# TMS320F280049 register map
Vendor: Texas Instruments; Series: C2000 F28004x; File version: 0.2.0-generated
Registers are 16-bit, read-write, reset 0x0 unless marked. A register's access mark holds for its fields unless they carry their own. Offsets are from the block's base; [hi:lo] are bit positions; {n}, {i} and the like mark numbered series.

## MEMCFGREGS — MEM CFG Registers
Base 0x000BE800
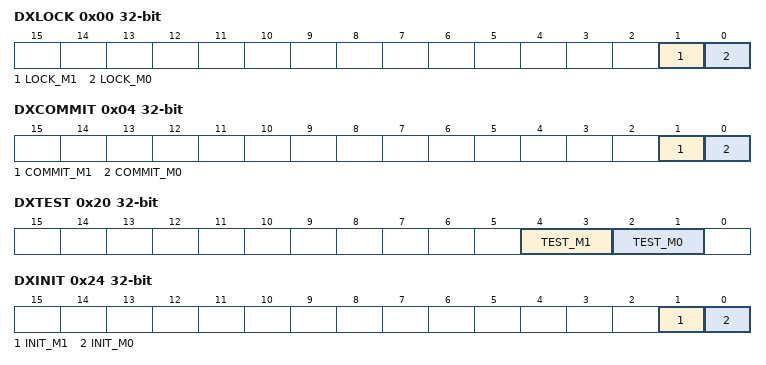
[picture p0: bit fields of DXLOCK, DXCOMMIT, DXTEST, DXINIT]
0x00 DXLOCK 32-bit — Dedicated RAM Config Lock Register
  [1] LOCK_M1 — M1 RAM Lock bits
  [0] LOCK_M0 — M0 RAM Lock bits
0x04 DXCOMMIT 32-bit — Dedicated RAM Config Lock Commit Register
  [1] COMMIT_M1 — M1 RAM Permanent Lock bits
  [0] COMMIT_M0 — M0 RAM Permanent Lock bits
0x10 DXACCPROT0 32-bit — Dedicated RAM Config Register
0x20 DXTEST 32-bit — Dedicated RAM TEST Register
  [4:3] TEST_M1 — Selects the different modes for M1 RAM
  [2:1] TEST_M0 — Selects the different modes for M0 RAM
0x24 DXINIT 32-bit — Dedicated RAM Init Register
  [1] INIT_M1 — RAM Initialization control for M1 RAM.
  [0] INIT_M0 — RAM Initialization control for M0 RAM.
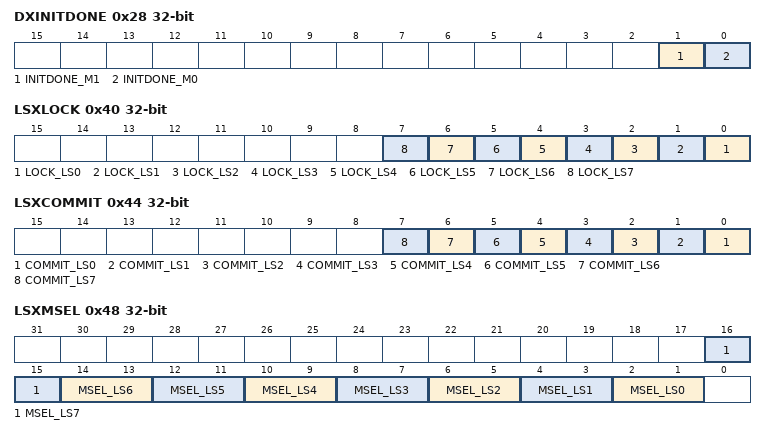
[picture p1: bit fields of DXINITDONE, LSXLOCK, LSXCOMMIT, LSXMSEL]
0x28 DXINITDONE 32-bit — Dedicated RAM InitDone Status Register
  [1] INITDONE_M1 — RAM Initialization status for M1 RAM.
  [0] INITDONE_M0 — RAM Initialization status for M0 RAM.
0x40 LSXLOCK 32-bit — Local Shared RAM Config Lock Register
  [n] LOCK_LS{n} (n=0..7) — LS{n} RAM Lock bits
0x44 LSXCOMMIT 32-bit — Local Shared RAM Config Lock Commit Register
  [n] COMMIT_LS{n} (n=0..7) — LS{n} RAM Permanent Lock bits
0x48 LSXMSEL 32-bit — Local Shared RAM Master Sel Register
  [2n+2:2n+1] MSEL_LS{n} (n=0..7) — Master Select for LS{n} RAM
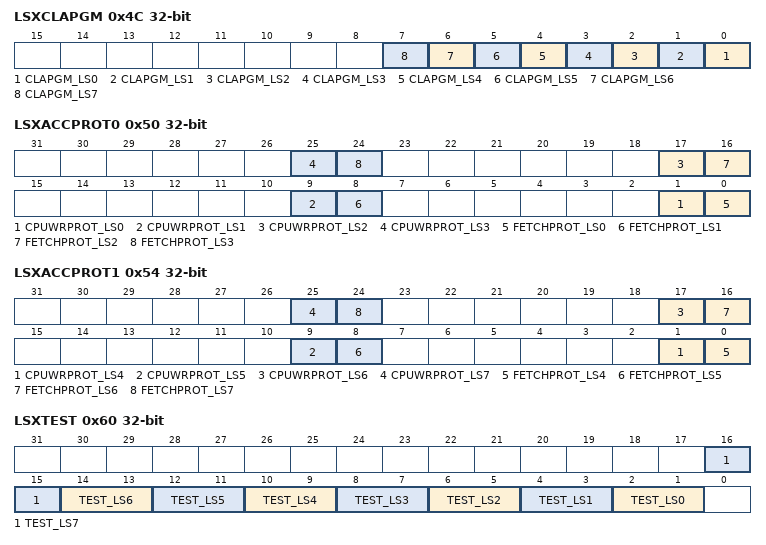
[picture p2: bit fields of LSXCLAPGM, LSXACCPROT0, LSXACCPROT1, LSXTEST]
0x4C LSXCLAPGM 32-bit — Local Shared RAM Prog/Exe control Register
  [n] CLAPGM_LS{n} (n=0..7) — Selects LS{n} RAM as program vs data memory for CLA
0x50 LSXACCPROT0 32-bit — Local Shared RAM Config Register 0
  [8n+1] CPUWRPROT_LS{n} (n=0..3) — CPU WR Protection For LS{n} RAM
  [8n] FETCHPROT_LS{n} (n=0..3) — Fetch Protection For LS{n} RAM
0x54 LSXACCPROT1 32-bit — Local Shared RAM Config Register 1
  [8n-31] CPUWRPROT_LS{n} (n=4..7) — CPU WR Protection For LS{n} RAM
  [8n-32] FETCHPROT_LS{n} (n=4..7) — Fetch Protection For LS{n} RAM
0x60 LSXTEST 32-bit — Local Shared RAM TEST Register
  [2n+2:2n+1] TEST_LS{n} (n=0..7) — Selects the different modes for LS{n} RAM
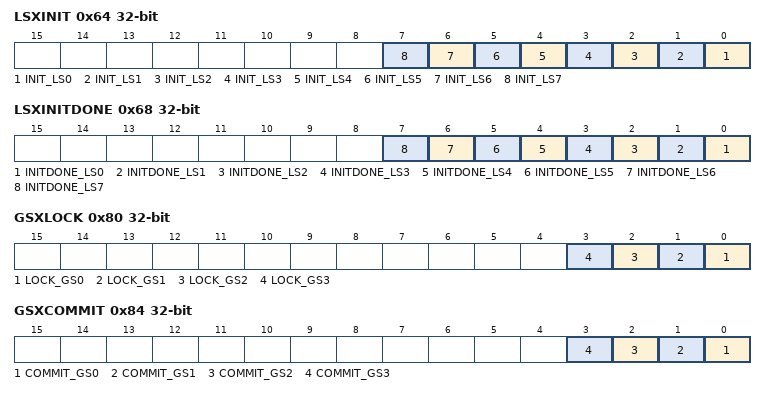
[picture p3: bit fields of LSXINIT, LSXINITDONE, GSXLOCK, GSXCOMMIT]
0x64 LSXINIT 32-bit — Local Shared RAM Init Register
  [n] INIT_LS{n} (n=0..7) — RAM Initialization control for LS{n} RAM.
0x68 LSXINITDONE 32-bit — Local Shared RAM InitDone Status Register
  [n] INITDONE_LS{n} (n=0..7) — RAM Initialization status for LS{n} RAM.
0x80 GSXLOCK 32-bit — Global Shared RAM Config Lock Register
  [n] LOCK_GS{n} (n=0..3) — GS{n} RAM Lock bits
0x84 GSXCOMMIT 32-bit — Global Shared RAM Config Lock Commit Register
  [n] COMMIT_GS{n} (n=0..3) — GS{n} RAM Permanent Lock bits
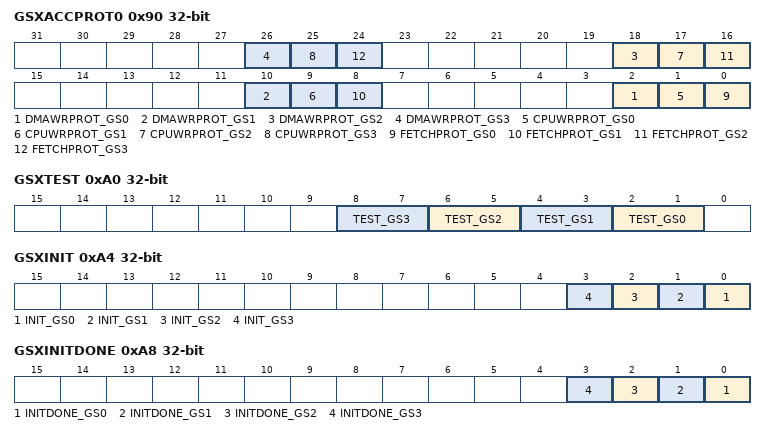
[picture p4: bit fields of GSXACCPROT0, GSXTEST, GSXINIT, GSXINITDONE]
0x90 GSXACCPROT0 32-bit — Global Shared RAM Config Register 0
  [8n+2] DMAWRPROT_GS{n} (n=0..3) — DMA WR Protection For GS{n} RAM
  [8n+1] CPUWRPROT_GS{n} (n=0..3) — CPU WR Protection For GS{n} RAM
  [8n] FETCHPROT_GS{n} (n=0..3) — Fetch Protection For GS{n} RAM
{0x90+4i} GSXACCPROT{i} 32-bit (i=1..3) — Global Shared RAM Config Register {i}
0xA0 GSXTEST 32-bit — Global Shared RAM TEST Register
  [2n+2:2n+1] TEST_GS{n} (n=0..3) — Selects the different modes for GS{n} RAM
0xA4 GSXINIT 32-bit — Global Shared RAM Init Register
  [n] INIT_GS{n} (n=0..3) — RAM Initialization control for GS{n} RAM.
0xA8 GSXINITDONE 32-bit — Global Shared RAM InitDone Status Register
  [n] INITDONE_GS{n} (n=0..3) — RAM Initialization status for GS{n} RAM.
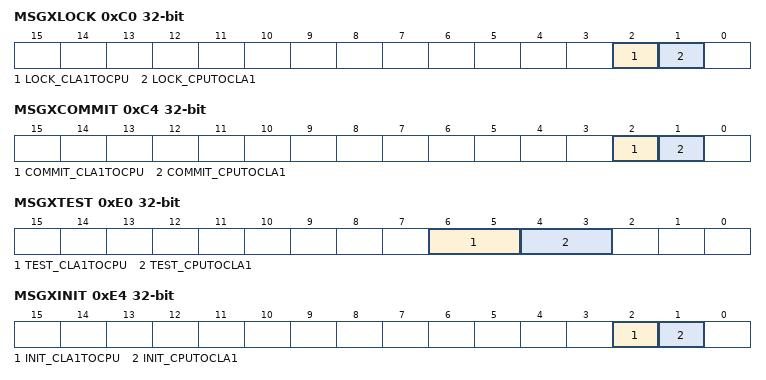
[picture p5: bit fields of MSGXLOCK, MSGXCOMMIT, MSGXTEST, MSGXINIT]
0xC0 MSGXLOCK 32-bit — Message RAM Config Lock Register
  [2] LOCK_CLA1TOCPU — CLA1TOCPU RAM Lock bits
  [1] LOCK_CPUTOCLA1 — CPUTOCLA1 RAM Lock bits
0xC4 MSGXCOMMIT 32-bit — Message RAM Config Lock Commit Register
  [2] COMMIT_CLA1TOCPU — CLA1TOCPU RAM control fields COMMIT bit
  [1] COMMIT_CPUTOCLA1 — CPUTOCLA1 RAM control fields COMMIT bit
0xE0 MSGXTEST 32-bit — Message RAM TEST Register
  [6:5] TEST_CLA1TOCPU — CLA1 to CPU MSG RAM Mode Select
  [4:3] TEST_CPUTOCLA1 — CPU to CLA1 MSG RAM Mode Select
0xE4 MSGXINIT 32-bit — Message RAM Init Register
  [2] INIT_CLA1TOCPU — Initialization control for CLA1TOCPU MSG RAM
  [1] INIT_CPUTOCLA1 — Initialization control for CPUTOCLA1 MSG RAM
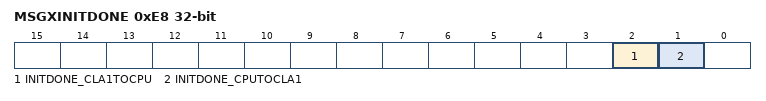
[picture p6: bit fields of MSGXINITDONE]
0xE8 MSGXINITDONE 32-bit — Message RAM InitDone Status Register
  [2] INITDONE_CLA1TOCPU — Initialization status for CLA1 to CPU MSG RAM
  [1] INITDONE_CPUTOCLA1 — Initialization status for CPU to CLA1 MSG RAM
